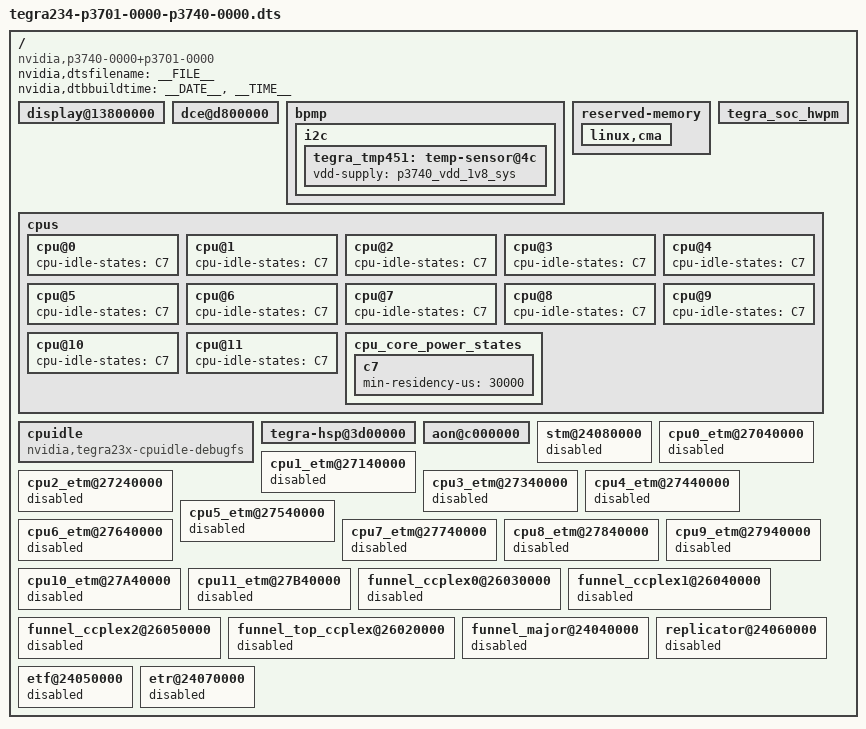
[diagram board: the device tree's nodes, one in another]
/*
 * Top level DTS file for CVM:P3701-0000 and CVB:P3740-0000.
 *
 * Copyright (c) 2021-2023, NVIDIA CORPORATION.  All rights reserved.
 *
 * This program is free software; you can redistribute it and/or modify
 * it under the terms of the GNU General Public License as published by
 * the Free Software Foundation; version 2 of the License.
 *
 * This program is distributed in the hope that it will be useful, but WITHOUT
 * ANY WARRANTY; without even the implied warranty of MERCHANTABILITY or
 * FITNESS FOR A PARTICULAR PURPOSE.  See the GNU General Public License for
 * more details.
 */

/dts-v1/;
#include "cvm/tegra234-p3701-0000.dtsi"
#include "cvb/tegra234-p3740-0000-a00.dtsi"
#include "tegra234-power-tree-p3701-0000-p3740-0000.dtsi"
#include "tegra234-dcb-p3701-0000-a02-p3740-0000-a00.dtsi"
#include <tegra234-soc/tegra234-cpuidle.dtsi>
#include <t234-common-cvb/tegra234-pwm.dtsi>
#include <t234-common-cvm/tegra234-thermal.dtsi>
#include <t234-common-cvm/tegra234-thermal-cooling.dtsi>
#include <tegra234-soc/mods-simple-bus.dtsi>
#include <tegra234-soc/tegra234-soc-hwpm.dtsi>

/ {
	nvidia,dtsfilename = __FILE__;
	nvidia,dtbbuildtime = __DATE__, __TIME__;

	compatible = "nvidia,p3740-0000+p3701-0000", "nvidia,tegra234", "nvidia,tegra23x";

	display@13800000 {
		status = "okay";
	};

	dce@d800000 {
		status = "okay";
	};

	bpmp {
		i2c {
			tegra_tmp451: temp-sensor@4c {
				vdd-supply = <&p3740_vdd_1v8_sys>;
			};
		};
	};

	reserved-memory {
		linux,cma {
			status = "okay";
		};
	};

tegra_soc_hwpm {
		status = "okay";
	};

	cpus {
		cpu@0 {
			cpu-idle-states = <&C7>;
		};

		cpu@1 {
			cpu-idle-states = <&C7>;
		};

		cpu@2 {
			cpu-idle-states = <&C7>;
		};

		cpu@3 {
			cpu-idle-states = <&C7>;
		};

		cpu@4 {
			cpu-idle-states = <&C7>;
		};

		cpu@5 {
			cpu-idle-states = <&C7>;
		};

		cpu@6 {
			cpu-idle-states = <&C7>;
		};

		cpu@7 {
			cpu-idle-states = <&C7>;
		};

		cpu@8 {
			cpu-idle-states = <&C7>;
		};

		cpu@9 {
			cpu-idle-states = <&C7>;
		};

		cpu@10 {
			cpu-idle-states = <&C7>;
		};

		cpu@11 {
			cpu-idle-states = <&C7>;
		};

		cpu_core_power_states {
			c7 {
				min-residency-us = <30000>;
				status = "okay";
			};
		};
	};

	cpuidle {
		compatible = "nvidia,tegra23x-cpuidle-debugfs";
		status = "okay";
	};

	tegra-hsp@3d00000 {
		status = "okay";
	};

	aon@c000000 {
		status = "okay";
	};

	stm@24080000 {
		status = "disabled";
	};

	cpu0_etm@27040000 {
		status = "disabled";
	};

	cpu1_etm@27140000 {
		status = "disabled";
	};

	cpu2_etm@27240000 {
		status = "disabled";
	};

	cpu3_etm@27340000 {
		status = "disabled";
	};

	cpu4_etm@27440000 {
		status = "disabled";
	};

	cpu5_etm@27540000 {
		status = "disabled";
	};

	cpu6_etm@27640000 {
		status = "disabled";
	};

	cpu7_etm@27740000 {
		status = "disabled";
	};

	cpu8_etm@27840000 {
		status = "disabled";
	};

	cpu9_etm@27940000 {
		status = "disabled";
	};

	cpu10_etm@27A40000 {
		status = "disabled";
	};

	cpu11_etm@27B40000 {
		status = "disabled";
	};

	funnel_ccplex0@26030000 {
		status = "disabled";
	};

	funnel_ccplex1@26040000 {
		status = "disabled";
	};

	funnel_ccplex2@26050000 {
		status = "disabled";
	};

	funnel_top_ccplex@26020000 {
		status = "disabled";
	};

	funnel_major@24040000 {
		status = "disabled";
	};

	replicator@24060000 {
		status = "disabled";
	};

	etf@24050000 {
		status = "disabled";
	};

	etr@24070000 {
		status = "disabled";
	};
};
